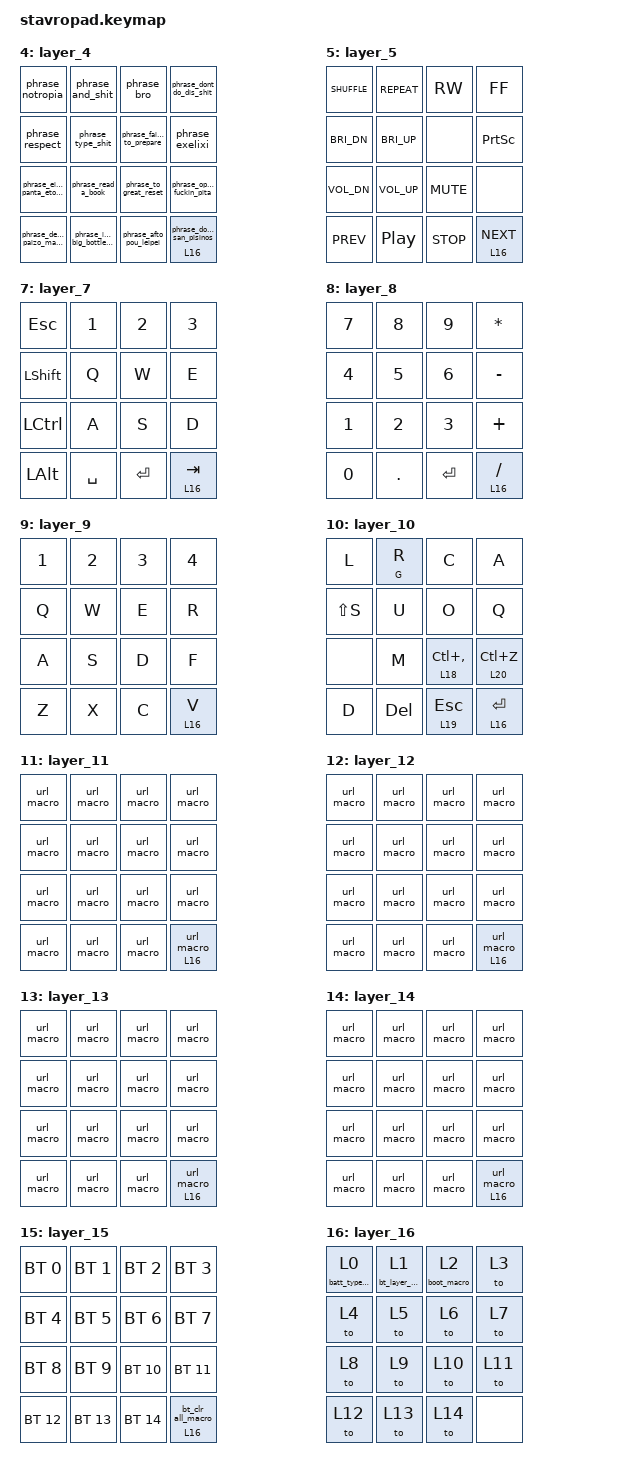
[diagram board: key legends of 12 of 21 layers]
#include <behaviors.dtsi>
#include <dt-bindings/zmk/keys.h>
#include <dt-bindings/zmk/bt.h>
#include <dt-bindings/zmk/pointing.h>
#include <behaviors/batt_type.dtsi>

/ {
    macros {
        url_macro: url_macro {
            compatible = "zmk,behavior-macro";
            #binding-cells = <0>;
            bindings = <&kp H &kp T &kp T &kp P &kp S &kp COLON &kp FSLH &kp FSLH &kp W &kp W &kp W &kp DOT &kp S &kp T &kp A &kp V &kp R &kp O &kp S &kp DOT &kp I &kp O>;
        };

        phrase_notropia: phrase_notropia {
            compatible = "zmk,behavior-macro";
            #binding-cells = <0>;
            bindings = <&kp N &kp O &kp T &kp R &kp O &kp P &kp I &kp A &kp SPACE>;
        };

        phrase_bro: phrase_bro {
            compatible = "zmk,behavior-macro";
            #binding-cells = <0>;
            bindings = <&kp B &kp R &kp O &kp SPACE>;
        };

        phrase_type_shit: phrase_type_shit {
            compatible = "zmk,behavior-macro";
            #binding-cells = <0>;
            bindings = <&kp T &kp Y &kp P &kp E &kp SPACE &kp S &kp H &kp I &kp T &kp SPACE>;
        };

        phrase_dont_do_dis_shit: phrase_dont_do_dis_shit {
            compatible = "zmk,behavior-macro";
            #binding-cells = <0>;
            bindings = <&kp D &kp O &kp N &kp SQT &kp T &kp SPACE &kp D &kp O &kp SPACE &kp D &kp I &kp S &kp SPACE &kp S &kp H &kp I &kp T &kp COMMA &kp SPACE &kp D &kp O &kp N &kp SQT &kp T &kp SPACE &kp D &kp O &kp SPACE &kp D &kp A &kp T &kp COMMA &kp SPACE &kp D &kp O &kp SPACE &kp D &kp I &kp S &kp COMMA &kp SPACE &kp D &kp O &kp SPACE &kp D &kp A &kp T &kp SPACE>;
        };

        phrase_respect: phrase_respect {
            compatible = "zmk,behavior-macro";
            #binding-cells = <0>;
            bindings = <&kp R &kp E &kp S &kp P &kp E &kp C &kp T &kp SPACE>;
        };

        phrase_and_shit: phrase_and_shit {
            compatible = "zmk,behavior-macro";
            #binding-cells = <0>;
            bindings = <&kp A &kp N &kp D &kp SPACE &kp S &kp H &kp I &kp T &kp SPACE>;
        };

        phrase_failing_to_prepare: phrase_failing_to_prepare {
            compatible = "zmk,behavior-macro";
            #binding-cells = <0>;
            bindings = <&kp F &kp A &kp I &kp L &kp I &kp N &kp G &kp SPACE &kp T &kp O &kp SPACE &kp P &kp R &kp E &kp P &kp A &kp R &kp E &kp SPACE &kp I &kp S &kp SPACE &kp P &kp R &kp E &kp P &kp A &kp R &kp I &kp N &kp G &kp SPACE &kp T &kp O &kp SPACE &kp F &kp A &kp I &kp L &kp SPACE>;
        };

        phrase_exelixi: phrase_exelixi {
            compatible = "zmk,behavior-macro";
            #binding-cells = <0>;
            bindings = <&kp E &kp X &kp E &kp L &kp I &kp X &kp I &kp SPACE>;
        };

        phrase_eimai_panta_etoimos: phrase_eimai_panta_etoimos {
            compatible = "zmk,behavior-macro";
            #binding-cells = <0>;
            bindings = <&kp E &kp I &kp M &kp A &kp I &kp SPACE &kp P &kp A &kp N &kp T &kp A &kp SPACE &kp E &kp T &kp O &kp I &kp M &kp O &kp S &kp SPACE>;
        };

        phrase_read_a_book: phrase_read_a_book {
            compatible = "zmk,behavior-macro";
            #binding-cells = <0>;
            bindings = <&kp R &kp E &kp A &kp D &kp SPACE &kp A &kp SPACE &kp B &kp O &kp O &kp K &kp SPACE>;
        };

        phrase_to_great_reset: phrase_to_great_reset {
            compatible = "zmk,behavior-macro";
            #binding-cells = <0>;
            bindings = <&kp T &kp O &kp SPACE &kp G &kp R &kp E &kp A &kp T &kp SPACE &kp R &kp E &kp S &kp E &kp T &kp SPACE>;
        };

        phrase_open_the_fuckin_pita: phrase_open_the_fuckin_pita {
            compatible = "zmk,behavior-macro";
            #binding-cells = <0>;
            bindings = <&kp O &kp P &kp E &kp N &kp SPACE &kp T &kp H &kp E &kp SPACE &kp F &kp U &kp C &kp K &kp I &kp N &kp SPACE &kp P &kp I &kp T &kp A &kp SPACE>;
        };

        phrase_imastan_big_bottle_boys: phrase_imastan_big_bottle_boys {
            compatible = "zmk,behavior-macro";
            #binding-cells = <0>;
            bindings = <&kp I &kp M &kp A &kp S &kp T &kp A &kp N &kp SPACE &kp B &kp I &kp G &kp SPACE &kp B &kp O &kp T &kp T &kp L &kp E &kp SPACE &kp B &kp O &kp Y &kp S &kp SPACE>;
        };

        phrase_afto_pou_leipei: phrase_afto_pou_leipei {
            compatible = "zmk,behavior-macro";
            #binding-cells = <0>;
            bindings = <&kp A &kp F &kp T &kp O &kp SPACE &kp P &kp O &kp U &kp SPACE &kp L &kp E &kp I &kp P &kp E &kp I &kp SPACE &kp E &kp I &kp N &kp A &kp I &kp SPACE &kp T &kp O &kp SPACE &kp M &kp I &kp A &kp L &kp O &kp SPACE>;
        };

        phrase_de_to_paizo_magkas: phrase_de_to_paizo_magkas {
            compatible = "zmk,behavior-macro";
            #binding-cells = <0>;
            bindings = <&kp D &kp E &kp SPACE &kp T &kp O &kp SPACE &kp P &kp A &kp I &kp Z &kp O &kp SPACE &kp M &kp A &kp G &kp K &kp A &kp S &kp SPACE>;
        };

        phrase_doulevo_san_pisinos: phrase_doulevo_san_pisinos {
            compatible = "zmk,behavior-macro";
            #binding-cells = <0>;
            bindings = <&kp D &kp O &kp U &kp L &kp E &kp V &kp O &kp SPACE &kp S &kp A &kp N &kp SPACE &kp P &kp I &kp S &kp I &kp N &kp O &kp S &kp SPACE>;
        };

        // Wrapper macro to give &bootloader a binding cell for use with hold-tap.
        boot_macro: boot_macro {
            compatible = "zmk,behavior-macro-one-param";
            #binding-cells = <1>;
            bindings = <&bootloader>;
        };

        // Wrapper macro for &batt_type to give it a binding cell for use with hold-tap.
        batt_type_macro: batt_type_macro {
            compatible = "zmk,behavior-macro-one-param";
            #binding-cells = <1>;
            bindings = <&batt_type>;
        };

        // Wrapper macro to switch to BT layer for use with hold-tap.
        bt_layer_macro: bt_layer_macro {
            compatible = "zmk,behavior-macro-one-param";
            #binding-cells = <1>;
            bindings = <&to 15>;
        };

        // Wrapper macro to select BT profile 14 for use with hold-tap.
        bt_sel_14_macro: bt_sel_14_macro {
            compatible = "zmk,behavior-macro";
            #binding-cells = <0>;
            bindings = <&bt BT_SEL 14>;
        };

        // Wrapper macro to clear all BT bonds for use with hold-tap.
        bt_clr_all_macro: bt_clr_all_macro {
            compatible = "zmk,behavior-macro";
            #binding-cells = <0>;
            bindings = <&bt BT_CLR_ALL>;
        };

        // OnShape sketch tool macros.
        os_point: os_point {
            compatible = "zmk,behavior-macro";
            #binding-cells = <0>;
            bindings = <&kp LS(S)>;
        };

        os_new_sketch: os_new_sketch {
            compatible = "zmk,behavior-macro";
            #binding-cells = <0>;
            bindings = <&kp LS(S)>;
        };

        os_extrude: os_extrude {
            compatible = "zmk,behavior-macro";
            #binding-cells = <0>;
            bindings = <&kp LS(E)>;
        };

        os_revolve: os_revolve {
            compatible = "zmk,behavior-macro";
            #binding-cells = <0>;
            bindings = <&kp LS(W)>;
        };

        os_sweep: os_sweep {
            compatible = "zmk,behavior-macro";
            #binding-cells = <0>;
            bindings = <&kp LS(W)>;
        };

        os_loft: os_loft {
            compatible = "zmk,behavior-macro";
            #binding-cells = <0>;
            bindings = <&kp LS(L)>;
        };

        os_fillet: os_fillet {
            compatible = "zmk,behavior-macro";
            #binding-cells = <0>;
            bindings = <&kp LS(F)>;
        };

        os_chamfer: os_chamfer {
            compatible = "zmk,behavior-macro";
            #binding-cells = <0>;
            bindings = <&kp LS(H)>;
        };

        os_shell: os_shell {
            compatible = "zmk,behavior-macro";
            #binding-cells = <0>;
            bindings = <&kp LS(Q)>;
        };

        os_draft: os_draft {
            compatible = "zmk,behavior-macro";
            #binding-cells = <0>;
            bindings = <&kp LS(D)>;
        };

        os_pattern: os_pattern {
            compatible = "zmk,behavior-macro";
            #binding-cells = <0>;
            bindings = <&kp LS(P)>;
        };

        os_mirror_feat: os_mirror_feat {
            compatible = "zmk,behavior-macro";
            #binding-cells = <0>;
            bindings = <&kp LS(M)>;
        };

        os_boolean: os_boolean {
            compatible = "zmk,behavior-macro";
            #binding-cells = <0>;
            bindings = <&kp LS(B)>;
        };

        os_split: os_split {
            compatible = "zmk,behavior-macro";
            #binding-cells = <0>;
            bindings = <&kp LS(I)>;
        };

        os_plane: os_plane {
            compatible = "zmk,behavior-macro";
            #binding-cells = <0>;
            bindings = <&kp LS(N)>;
        };

        os_sketch_on: os_sketch_on {
            compatible = "zmk,behavior-macro";
            #binding-cells = <0>;
            bindings = <&kp LS(S)>;
        };

        // Types "mm" for millimeters.
        os_mm: os_mm {
            compatible = "zmk,behavior-macro";
            #binding-cells = <0>;
            bindings = <&kp M &kp M>;
        };

    };

    behaviors {
        // Hold for bootloader, tap for layer switch.
        boot_hold: boot_hold {
            compatible = "zmk,behavior-hold-tap";
            #binding-cells = <2>;
            flavor = "hold-preferred";
            tapping-term-ms = <1000>;
            bindings = <&boot_macro>, <&to>;
        };

        // Hold for battery voltage, tap for layer switch.
        batt_hold: batt_hold {
            compatible = "zmk,behavior-hold-tap";
            #binding-cells = <2>;
            flavor = "hold-preferred";
            tapping-term-ms = <1000>;
            bindings = <&batt_type_macro>, <&to>;
        };

        // Hold for BT layer, tap for layer switch.
        bt_layer_hold: bt_layer_hold {
            compatible = "zmk,behavior-hold-tap";
            #binding-cells = <2>;
            flavor = "hold-preferred";
            tapping-term-ms = <1000>;
            bindings = <&bt_layer_macro>, <&to>;
        };

        // Hold-tap behaviors for key 15 on each layer.
        // Hold activates layer 16 (layer selection), tap performs layer-specific action.

        // Layers 0-3: Tap sends a keypress, hold activates layer 16.
        lt_layer0: lt_layer0 {
            compatible = "zmk,behavior-hold-tap";
            #binding-cells = <2>;
            flavor = "hold-preferred";
            tapping-term-ms = <200>;
            bindings = <&mo>, <&kp>;
        };

        // Layer 4: Tap sends "doulevo san pisinos" macro.
        lt_layer4: lt_layer4 {
            compatible = "zmk,behavior-hold-tap";
            #binding-cells = <2>;
            flavor = "hold-preferred";
            tapping-term-ms = <200>;
            bindings = <&mo>, <&phrase_doulevo_san_pisinos>;
        };

        // Layer 5: Tap sends play/pause.
        lt_layer5: lt_layer5 {
            compatible = "zmk,behavior-hold-tap";
            #binding-cells = <2>;
            flavor = "hold-preferred";
            tapping-term-ms = <200>;
            bindings = <&mo>, <&kp>;
        };

        // Layer 6: Tap sends left click.
        lt_layer6: lt_layer6 {
            compatible = "zmk,behavior-hold-tap";
            #binding-cells = <2>;
            flavor = "hold-preferred";
            tapping-term-ms = <200>;
            bindings = <&mo>, <&mkp>;
        };

        // Placeholder layers (10-14): Tap sends url_macro.
        lt_layer7: lt_layer7 {
            compatible = "zmk,behavior-hold-tap";
            #binding-cells = <2>;
            flavor = "hold-preferred";
            tapping-term-ms = <200>;
            bindings = <&mo>, <&url_macro>;
        };

        // Layer 7 (Gaming): Tap sends Tab.
        lt_layer7_gaming: lt_layer7_gaming {
            compatible = "zmk,behavior-hold-tap";
            #binding-cells = <2>;
            flavor = "hold-preferred";
            tapping-term-ms = <200>;
            bindings = <&mo>, <&kp>;
        };

        // Layer 8 (Numpad): Tap sends a keypress, hold activates layer 16.
        lt_layer8: lt_layer8 {
            compatible = "zmk,behavior-hold-tap";
            #binding-cells = <2>;
            flavor = "hold-preferred";
            tapping-term-ms = <200>;
            bindings = <&mo>, <&kp>;
        };

        // Layer 9 (QWERTY): Tap sends a keypress, hold activates layer 16.
        lt_layer9: lt_layer9 {
            compatible = "zmk,behavior-hold-tap";
            #binding-cells = <2>;
            flavor = "hold-preferred";
            tapping-term-ms = <200>;
            bindings = <&mo>, <&kp>;
        };

        // Layer 15 (Bluetooth): Tap clears all BT bonds.
        lt_layer15: lt_layer15 {
            compatible = "zmk,behavior-hold-tap";
            #binding-cells = <2>;
            flavor = "hold-preferred";
            tapping-term-ms = <200>;
            bindings = <&mo>, <&bt_clr_all_macro>;
        };

        // Layer 10 (OnShape Sketch): Tap sends Dimension (D), hold activates layer 16.
        lt_layer10: lt_layer10 {
            compatible = "zmk,behavior-hold-tap";
            #binding-cells = <2>;
            flavor = "hold-preferred";
            tapping-term-ms = <200>;
            bindings = <&mo>, <&kp>;
        };

        // OnShape long-press behaviors (150ms threshold).
        // Tap: corner rect (G), Hold: center rect (R).
        os_rect_ht: os_rect_ht {
            compatible = "zmk,behavior-hold-tap";
            #binding-cells = <2>;
            flavor = "hold-preferred";
            tapping-term-ms = <150>;
            bindings = <&kp>, <&kp>;
        };

        // Layer 10 key 13: Tap sends Esc, hold activates layer 19 (Features).
        os_esc_features: os_esc_features {
            compatible = "zmk,behavior-hold-tap";
            #binding-cells = <2>;
            flavor = "hold-preferred";
            tapping-term-ms = <200>;
            bindings = <&mo>, <&kp>;
        };

        // Tap sends key, hold activates layer 18 (OnShape Constraints).
        os_hold_constraints: os_hold_constraints {
            compatible = "zmk,behavior-hold-tap";
            #binding-cells = <2>;
            flavor = "hold-preferred";
            tapping-term-ms = <200>;
            bindings = <&mo>, <&kp>;
        };

        // Key 11: Tap sends Ctrl+Z (undo), hold activates layer 20 (Numbers).
        os_undo_numbers: os_undo_numbers {
            compatible = "zmk,behavior-hold-tap";
            #binding-cells = <2>;
            flavor = "hold-preferred";
            tapping-term-ms = <200>;
            bindings = <&mo>, <&kp>;
        };
    };

    keymap {
        compatible = "zmk,keymap";

        // Layer 0: Numbers and symbols.
        layer_0 {
            bindings = <
                &kp RC(LS(LG(N1)))   &kp RC(LS(LG(N2)))   &kp RC(LS(LG(N3)))   &kp RC(LS(LG(N4)))
                &kp RC(LS(LG(N5)))   &kp RC(LS(LG(N6)))   &kp RC(LS(LG(N7)))   &kp RC(LS(LG(N8)))
                &kp RC(LS(LG(N9)))   &kp RC(LS(LG(N0)))   &kp RC(LS(LG(MINUS))) &kp RC(LS(LG(EQUAL)))
                &kp RC(LS(LG(GRAVE))) &kp RC(LS(LG(LBKT))) &kp RC(LS(LG(RBKT))) &lt_layer0 16 RC(LS(LG(BSLH)))
            >;
        };

        // Layer 1: Letters A-P.
        layer_1 {
            bindings = <
                &kp RC(LS(LG(A)))    &kp RC(LS(LG(B)))    &kp RC(LS(LG(C)))    &kp RC(LS(LG(D)))
                &kp RC(LS(LG(E)))    &kp RC(LS(LG(F)))    &kp RC(LS(LG(G)))    &kp RC(LS(LG(H)))
                &kp RC(LS(LG(I)))    &kp RC(LS(LG(J)))    &kp RC(LS(LG(K)))    &kp RC(LS(LG(L)))
                &kp RC(LS(LG(M))) &kp RC(LS(LG(N))) &kp RC(LS(LG(O))) &lt_layer0 16 RC(LS(LG(P)))
            >;
        };

        // Layer 2: Letters Q-Z and punctuation.
        layer_2 {
            bindings = <
                &kp RC(LS(LG(Q)))    &kp RC(LS(LG(R)))    &kp RC(LS(LG(S)))    &kp RC(LS(LG(T)))
                &kp RC(LS(LG(U)))    &kp RC(LS(LG(V)))    &kp RC(LS(LG(W)))    &kp RC(LS(LG(X)))
                &kp RC(LS(LG(Y)))    &kp RC(LS(LG(Z)))    &kp RC(LS(LG(SEMI))) &kp RC(LS(LG(SQT)))
                &kp RC(LS(LG(COMMA))) &kp RC(LS(LG(DOT))) &kp RC(LS(LG(FSLH))) &lt_layer0 16 RC(LS(LG(SPACE)))
            >;
        };

        // Layer 3: Function keys and modifiers.
        layer_3 {
            bindings = <
                &kp RC(LS(LG(F1)))   &kp RC(LS(LG(F2)))   &kp RC(LS(LG(F3)))   &kp RC(LS(LG(F4)))
                &kp RC(LS(LG(F5)))   &kp RC(LS(LG(F6)))   &kp RC(LS(LG(F7)))   &kp RC(LS(LG(F8)))
                &kp RC(LS(LG(F9)))   &kp RC(LS(LG(F10)))  &kp RC(LS(LG(F11)))  &kp RC(LS(LG(F12)))
                &kp RC(LS(LG(TAB))) &kp RC(LS(LG(ESC))) &kp RC(LS(LG(RET))) &lt_layer0 16 RC(LS(LG(BSPC)))
            >;
        };

        layer_4 {
            bindings = <
                &phrase_notropia           &phrase_and_shit                &phrase_bro                  &phrase_dont_do_dis_shit
                &phrase_respect             &phrase_type_shit               &phrase_failing_to_prepare   &phrase_exelixi
                &phrase_eimai_panta_etoimos &phrase_read_a_book             &phrase_to_great_reset       &phrase_open_the_fuckin_pita
                &phrase_de_to_paizo_magkas &phrase_imastan_big_bottle_boys &phrase_afto_pou_leipei &lt_layer4 16 0
            >;
        };

        layer_5 {
            bindings = <
                &kp C_SHUFFLE  &kp C_REPEAT   &kp C_RW       &kp C_FF
                &kp C_BRI_DN   &kp C_BRI_UP   &none          &kp PSCRN
                &kp C_VOL_DN   &kp C_VOL_UP   &kp C_MUTE     &none
                &kp C_PREV &kp C_PP &kp C_STOP &lt_layer5 16 C_NEXT
            >;
        };

        layer_6 {
            bindings = <
                &mmv (MOVE_LEFT+MOVE_UP)        &mmv MOVE_UP                    &mmv (MOVE_RIGHT+MOVE_UP)       &msc SCRL_UP
                &mmv MOVE_LEFT                  &mo 17                          &mmv MOVE_RIGHT                 &msc SCRL_DOWN
                &mmv (MOVE_LEFT+MOVE_DOWN)      &mmv MOVE_DOWN                  &mmv (MOVE_RIGHT+MOVE_DOWN)     &mkp MB5
                &mkp LCLK                       &mkp MCLK                       &mkp RCLK                       &lt_layer6 16 MB4
            >;
        };

        // Layer 7: Gaming.
        layer_7 {
            bindings = <
                &kp ESC    &kp N1     &kp N2     &kp N3
                &kp LSHIFT &kp Q      &kp W      &kp E
                &kp LCTRL  &kp A      &kp S      &kp D
                &kp LALT &kp SPACE &kp RET &lt_layer7_gaming 16 TAB
            >;
        };

        // Layer 8: Numpad.
        layer_8 {
            bindings = <
                &kp N7  &kp N8  &kp N9  &kp STAR
                &kp N4  &kp N5  &kp N6  &kp MINUS
                &kp N1  &kp N2  &kp N3  &kp PLUS
                &kp N0 &kp DOT &kp RET &lt_layer8 16 SLASH
            >;
        };

        // Layer 9: QWERTY.
        layer_9 {
            bindings = <
                &kp N1 &kp N2 &kp N3 &kp N4
                &kp Q  &kp W  &kp E  &kp R
                &kp A  &kp S  &kp D  &kp F
                &kp Z &kp X &kp C &lt_layer9 16 V
            >;
        };

        // Layer 10: OnShape Sketch Tools.
        // Long-press key 1: Rect (tap=center r, hold=corner g).
        // Key 10: Tap sends Ctrl+, (preferences), hold activates layer 18 (Constraints).
        // Key 11: Tap sends Ctrl+Z (undo), hold activates layer 20 (Numbers).
        layer_10 {
            bindings = <
                &kp L              &os_rect_ht G R    &kp C              &kp A
                &kp LS(S)          &kp U              &kp O              &kp Q
                &none              &kp M              &os_hold_constraints 18 LC(COMMA) &os_undo_numbers 20 LC(Z)
                &kp D              &kp DEL            &os_esc_features 19 ESC &lt_layer10 16 RET
            >;
        };

        // Layer 11: Placeholder.
        layer_11 {
            bindings = <
                &url_macro &url_macro &url_macro &url_macro
                &url_macro &url_macro &url_macro &url_macro
                &url_macro &url_macro &url_macro &url_macro
                &url_macro &url_macro &url_macro &lt_layer7 16 0
            >;
        };

        // Layer 12: Placeholder.
        layer_12 {
            bindings = <
                &url_macro &url_macro &url_macro &url_macro
                &url_macro &url_macro &url_macro &url_macro
                &url_macro &url_macro &url_macro &url_macro
                &url_macro &url_macro &url_macro &lt_layer7 16 0
            >;
        };

        // Layer 13: Placeholder.
        layer_13 {
            bindings = <
                &url_macro &url_macro &url_macro &url_macro
                &url_macro &url_macro &url_macro &url_macro
                &url_macro &url_macro &url_macro &url_macro
                &url_macro &url_macro &url_macro &lt_layer7 16 0
            >;
        };

        // Layer 14: Placeholder.
        layer_14 {
            bindings = <
                &url_macro &url_macro &url_macro &url_macro
                &url_macro &url_macro &url_macro &url_macro
                &url_macro &url_macro &url_macro &url_macro
                &url_macro &url_macro &url_macro &lt_layer7 16 0
            >;
        };

        // Layer 15: Bluetooth control layer.
        layer_15 {
            bindings = <
                &bt BT_SEL 0   &bt BT_SEL 1   &bt BT_SEL 2   &bt BT_SEL 3
                &bt BT_SEL 4   &bt BT_SEL 5   &bt BT_SEL 6   &bt BT_SEL 7
                &bt BT_SEL 8   &bt BT_SEL 9   &bt BT_SEL 10  &bt BT_SEL 11
                &bt BT_SEL 12 &bt BT_SEL 13 &bt BT_SEL 14 &lt_layer15 16 0
            >;
        };

        // Layer 16: Layer selection (activated by holding key 15).
        // Tap keys 0-11 for layers 0-11, tap keys 12-14 for layers 12-14.
        // Hold keys 0-2 for 1 second for special functions (battery, Bluetooth, bootloader).
        layer_16 {
            bindings = <
                &batt_hold 0 0     &bt_layer_hold 0 1 &boot_hold 0 2     &to 3
                &to 4              &to 5              &to 6              &to 7
                &to 8              &to 9              &to 10             &to 11
                &to 12             &to 13             &to 14             &none
            >;
        };

        // Layer 17: Scroll sub-layer (activated by holding center key on layer 6).
        layer_17 {
            bindings = <
                &trans         &msc SCRL_LEFT &msc SCRL_UP   &msc SCRL_RIGHT
                &trans         &trans         &trans         &trans
                &trans         &msc SCRL_LEFT &msc SCRL_DOWN &msc SCRL_RIGHT
                &trans         &trans         &trans         &trans
            >;
        };

        // Layer 18: OnShape Constraints (activated by holding key 10 on layer 10).
        layer_18 {
            bindings = <
                &kp D          &kp H          &kp V          &kp I
                &kp T          &kp E          &kp B          &kp LS(L)
                &kp LS(O)      &kp LS(M)      &kp LS(Q)      &kp LS(J)
                &kp LS(K)      &kp LS(U)      &kp LS(G)      &none
            >;
        };

        // Layer 19: OnShape Features (activated by holding Esc on layer 10).
        layer_19 {
            bindings = <
                &os_extrude    &os_revolve    &none          &none
                &os_fillet     &none          &none          &none
                &none          &none          &none          &none
                &none          &none          &none          &none
            >;
        };

        // Layer 20: OnShape Numbers (activated by holding key 11 on layer 10).
        layer_20 {
            bindings = <
                &kp N7         &kp N8         &kp N9         &kp STAR
                &kp N4         &kp N5         &kp N6         &os_mm
                &kp N1         &kp N2         &kp N3         &none
                &kp N0         &kp DOT        &kp PLUS       &kp BSPC
            >;
        };
    };
};
